# S6E2H1xE register map
Vendor: Cypress; File version: 2.1
CPU: CM4 r0p1, little endian, MPU, FPU, 4 interrupt priority bits
Registers are 32-bit, read-write, reset 0x0 unless marked. A register's access mark holds for its fields unless they carry their own. Offsets are from the block's base; [hi:lo] are bit positions; 'fields as' and 'values as' point back to an identical list.

## MFT0 — Multifunction Timer 0
Base 0x40020000
Same registers: MFT1 0x40021000, MFT2 0x40022000
0x102 OCU_OCCP0 16-bit (OCU view) — OCU ch.0 Compare Value Store Register [HW]
0x106 OCU_OCCP1 16-bit (OCU view) — OCU ch.1 Compare Value Store Register [HW]
0x10A OCU_OCCP2 16-bit (OCU view) — OCU ch.2 Compare Value Store Register [HW]
0x10E OCU_OCCP3 16-bit (OCU view) — OCU ch.3 Compare Value Store Register [HW]
0x112 OCU_OCCP4 16-bit (OCU view) — OCU ch.4 Compare Value Store Register [HW]
0x116 OCU_OCCP5 16-bit (OCU view) — OCU ch.5 Compare Value Store Register [HW]
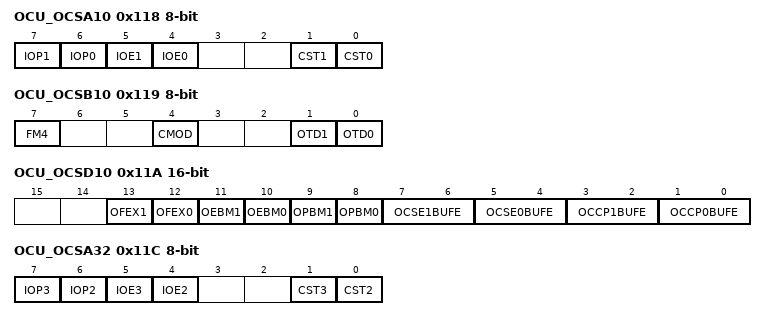
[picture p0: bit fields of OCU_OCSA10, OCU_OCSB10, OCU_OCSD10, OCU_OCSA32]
0x118 OCU_OCSA10 8-bit (OCU view) — OCU ch.0/1 Control Register A [BHW]
  [7] IOP1 — Indicates that a match has already been detected between FRT's count value and OCCP(1) value at OCU ch.(1)
  [6] IOP0 — Indicates that a match has already been detected between FRT's count value and OCCP(0) value at OCU ch.(0)
  [5] IOE1 — Generates interrupt when OCSA.IOP1 is set to 1
  [4] IOE0 — Generates interrupt when OCSA.IOP0 is set to 1
  [1] CST1 — Enables the operation of OCU ch.(1)
  [0] CST0 — Enables the operation of OCU ch.(0)
0x119 OCU_OCSB10 8-bit (OCU view) — OCU ch.0/1 Control Register B [BHW]
  [7] FM4 — selects FM4 mode for operating mode
  [4] CMOD — selects OCU's operation mode in combination with OCSC.MOD0 to MOD5
  [1] OTD1 — Indicates that the RT(1) output pin is in the High-level output state
  [0] OTD0 — Indicates that the RT(0) output pin is in the High-level output state
0x11A OCU_OCSD10 16-bit (OCU view) — OCU ch.0/1 Control Register D [BHW]
  [13] OFEX1 — extends the matching determination conditions of the connected FRT with the OCCP(1) register value
  [12] OFEX0 — extends the matching determination conditions of the connected FRT with the OCCP(0) register value
  [11] OEBM1 — sets the linked transfer settings with the FRT interrupt mask counter
  [10] OEBM0 — sets the linked transfer settings with the FRT interrupt mask counter
  [9] OPBM1 — sets the linked transfer settings with the FRT interrupt mask counter
  [8] OPBM0 — sets the linked transfer settings with the FRT interrupt mask counter
  [7:6] OCSE1BUFE — Enable buffer register function of OCSE(1)
  [5:4] OCSE0BUFE — Enable buffer register function of OCSE(0)
  [3:2] OCCP1BUFE — Enable buffer register function of OCCP(1)
  [1:0] OCCP0BUFE — Enable buffer register function of OCCP(0)
0x11C OCU_OCSA32 8-bit (OCU view) — OCU ch.2/3 Control Register A [BHW]
  [7] IOP3 — Indicates that a match has already been detected between FRT's count value and OCCP(3) value at OCU ch.(3)
  [6] IOP2 — Indicates that a match has already been detected between FRT's count value and OCCP(2) value at OCU ch.(2)
  [5] IOE3 — Generates interrupt when OCSA.IOP3 is set to 1
  [4] IOE2 — Generates interrupt when OCSA.IOP2 is set to 1
  [1] CST3 — Enables the operation of OCU ch.(3)
  [0] CST2 — Enables the operation of OCU ch.(2)
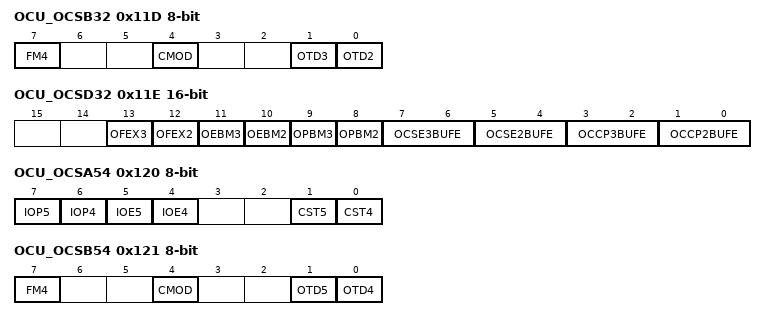
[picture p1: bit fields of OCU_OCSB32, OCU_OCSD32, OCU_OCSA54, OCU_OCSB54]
0x11D OCU_OCSB32 8-bit (OCU view) — OCU ch.2/3 Control Register B [BHW]
  [7] FM4 — selects FM4 mode for operating mode
  [4] CMOD — selects OCU's operation mode in combination with OCSC.MOD0 to MOD5
  [1] OTD3 — Indicates that the RT(3) output pin is in the High-level output state
  [0] OTD2 — Indicates that the RT(2) output pin is in the High-level output state
0x11E OCU_OCSD32 16-bit (OCU view) — OCU ch.2/3 Control Register D [BHW]
  [13] OFEX3 — extends the matching determination conditions of the connected FRT with the OCCP(3) register value
  [12] OFEX2 — extends the matching determination conditions of the connected FRT with the OCCP(2) register value
  [11] OEBM3 — sets the linked transfer settings with the FRT interrupt mask counter
  [10] OEBM2 — sets the linked transfer settings with the FRT interrupt mask counter
  [9] OPBM3 — sets the linked transfer settings with the FRT interrupt mask counter
  [8] OPBM2 — sets the linked transfer settings with the FRT interrupt mask counter
  [7:6] OCSE3BUFE — Enable buffer register function of OCSE(3)
  [5:4] OCSE2BUFE — Enable buffer register function of OCSE(2)
  [3:2] OCCP3BUFE — Enable buffer register function of OCCP(3)
  [1:0] OCCP2BUFE — Enable buffer register function of OCCP(2)
0x120 OCU_OCSA54 8-bit (OCU view) — OCU ch.4/5 Control Register A [BHW]
  [7] IOP5 — Indicates that a match has already been detected between FRT's count value and OCCP(5) value at OCU ch.(5)
  [6] IOP4 — Indicates that a match has already been detected between FRT's count value and OCCP(4) value at OCU ch.(4)
  [5] IOE5 — Generates interrupt when OCSA.IOP5 is set to 1
  [4] IOE4 — Generates interrupt when OCSA.IOP4 is set to 1
  [1] CST5 — Enables the operation of OCU ch.(5)
  [0] CST4 — Enables the operation of OCU ch.(4)
0x121 OCU_OCSB54 8-bit (OCU view) — OCU ch.4/5 Control Register B [BHW]
  [7] FM4 — selects FM4 mode for operating mode
  [4] CMOD — selects OCU's operation mode in combination with OCSC.MOD0 to MOD5
  [1] OTD5 — Indicates that the RT(5) output pin is in the High-level output state
  [0] OTD4 — Indicates that the RT(4) output pin is in the High-level output state
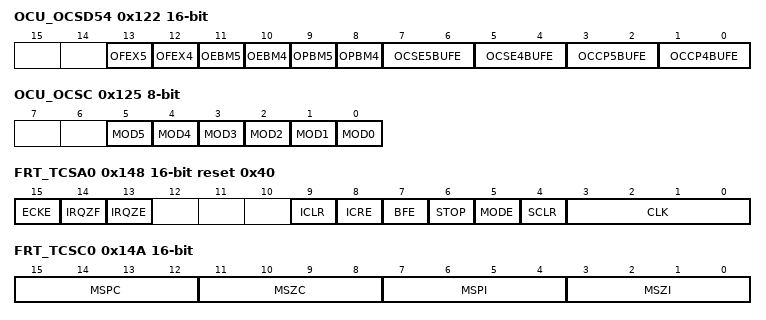
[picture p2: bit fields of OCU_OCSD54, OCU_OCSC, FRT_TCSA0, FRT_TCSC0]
0x122 OCU_OCSD54 16-bit (OCU view) — OCU ch.4/5 Control Register D [BHW]
  [13] OFEX5 — extends the matching determination conditions of the connected FRT with the OCCP(5) register value
  [12] OFEX4 — extends the matching determination conditions of the connected FRT with the OCCP(4) register value
  [11] OEBM5 — sets the linked transfer settings with the FRT interrupt mask counter
  [10] OEBM4 — sets the linked transfer settings with the FRT interrupt mask counter
  [9] OPBM5 — sets the linked transfer settings with the FRT interrupt mask counter
  [8] OPBM4 — sets the linked transfer settings with the FRT interrupt mask counter
  [7:6] OCSE5BUFE — Enable buffer register function of OCSE(5)
  [5:4] OCSE4BUFE — Enable buffer register function of OCSE(4)
  [3:2] OCCP5BUFE — Enable buffer register function of OCCP(5)
  [1:0] OCCP4BUFE — Enable buffer register function of OCCP(4)
0x125 OCU_OCSC 8-bit (OCU view) — OCU Control Register C [BHW]
  [5] MOD5 — OCSC.MOD4 and OCSC.MOD5 determine the operation mode of OCU ch.4,h.5 in combination with OCSB54.CMOD
  [4] MOD4 — OCSC.MOD4 and OCSC.MOD5 determine the operation mode of OCU ch.4,h.5 in combination with OCSB54.CMOD
  [3] MOD3 — OCSC.MOD2 and OCSC.MOD3 determine the operation mode of OCU ch.2,h.3 in combination with OCSB32.CMOD
  [2] MOD2 — OCSC.MOD2 and OCSC.MOD3 determine the operation mode of OCU ch.2,h.3 in combination with OCSB32.CMOD
  [1] MOD1 — OCSC.MOD0 and OCSC.MOD1 determine the operation mode of OCU ch.0,h.1 in combination with OCSB10.CMOD
  [0] MOD0 — OCSC.MOD0 and OCSC.MOD1 determine the operation mode of OCU ch.0,h.1 in combination with OCSB10.CMOD
0x128 OCU_OCSE0 16-bit (OCU view) — OCU ch.0 Control Register E [BHW]
  [15:0] OCSE — specify the setting conditions of the OCU's matching detection register (IOP0)
0x12C OCU_OCSE1 (OCU view) — OCU ch.1 Control Register E [BHW]
  [31:0] OCSE — specify the setting conditions of the OCU's matching detection register (IOP0/IOP1)
0x130 OCU_OCSE2 16-bit (OCU view) — OCU ch.2 Control Register E [BHW]
  fields as OCU_OCSE0
0x134 OCU_OCSE3 (OCU view) — OCU ch.3 Control Register E [BHW]
  fields as OCU_OCSE1
0x138 OCU_OCSE4 16-bit (OCU view) — OCU ch.4 Control Register E [BHW]
  fields as OCU_OCSE0
0x13C OCU_OCSE5 (OCU view) — OCU ch.5 Control Register E [BHW]
  fields as OCU_OCSE1
0x142 FRT_TCCP0 16-bit reset 0xFFFF (FRT view) — FRT-ch.0 Cycle Setting Register [HW]
  [15:0] TCCP — Count Cycle Setting Bits
0x146 FRT_TCDT0 16-bit (FRT view) — FRT-ch.0 Count Value Register [HW]
0x148 FRT_TCSA0 16-bit reset 0x40 (FRT view) — FRT-ch.0 Control Register A [BHW]
  [15] ECKE — Uses an external input clock (FRCK) as FRT's count clock
  [14] IRQZF — zero interrupt flag
  [13] IRQZE — Generates interrupt when TCSA.IRQZF is set to 1
  [9] ICLR — interrupt flag
  [8] ICRE — Generates interrupt when TCSA.ICLR is set to 1
  [7] BFE — Enables TCCP's buffer function
  [6] STOP — Puts FRT in stopping state
  [5] MODE — FRT's count mode
  [4] SCLR wo — FRT operation state initialization request
  [3:0] CLK — FRT clock cycle
0x14A FRT_TCSC0 16-bit (FRT view) — FRT-ch.0 Control Register C [HW]
  [15:12] MSPC ro — Current counter value of a Peak value detection mask counter
  [11:8] MSZC ro — Current counter value of a Zero value detection mask counter
  [7:4] MSPI — Masked Peak value detection number
  [3:0] MSZI — Masked Zero value detection number
0x14E FRT_TCCP1 16-bit reset 0xFFFF (FRT view) — FRT-ch.1 Cycle Setting Register [HW]
  [15:0] TCCP — Count Cycle Setting Bits
0x152 FRT_TCDT1 16-bit (FRT view) — FRT-ch.1 Count Value Register [HW]
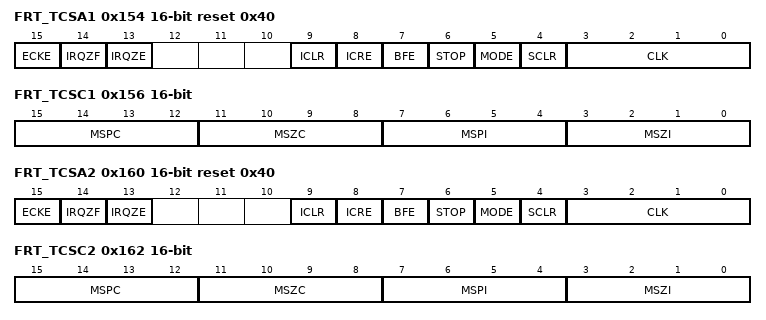
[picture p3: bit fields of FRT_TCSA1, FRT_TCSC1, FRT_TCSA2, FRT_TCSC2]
0x154 FRT_TCSA1 16-bit reset 0x40 (FRT view) — FRT-ch.1 Control Register A [BHW]
  fields as FRT_TCSA0
0x156 FRT_TCSC1 16-bit (FRT view) — FRT-ch.1 Control Register C [HW]
  fields as FRT_TCSC0
0x15A FRT_TCCP2 16-bit reset 0xFFFF (FRT view) — FRT-ch.2 Cycle Setting Register [HW]
  [15:0] TCCP — Count Cycle Setting Bits
0x15E FRT_TCDT2 16-bit (FRT view) — FRT-ch.2 Count Value Register [HW]
0x160 FRT_TCSA2 16-bit reset 0x40 (FRT view) — FRT-ch.2 Control Register A [BHW]
  fields as FRT_TCSA0
0x162 FRT_TCSC2 16-bit (FRT view) — FRT-ch.2 Control Register C [HW]
  fields as FRT_TCSC0
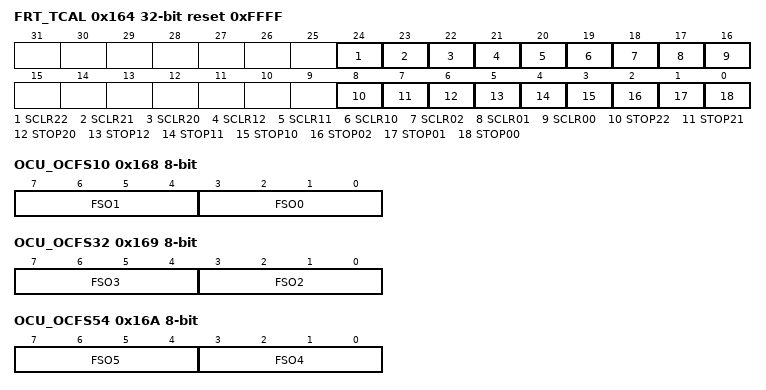
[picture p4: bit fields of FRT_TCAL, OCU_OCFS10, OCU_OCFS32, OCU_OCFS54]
0x164 FRT_TCAL reset 0xFFFF (FRT view) — FRT Simultaneous Start Control Register [W]
  [24] SCLR22 wo — Mirror register of the SCLR bit located in TCSA2 register of MFT-unit2
  [23] SCLR21 wo — Mirror register of the SCLR bit located in TCSA1 register of MFT-unit2
  [22] SCLR20 wo — Mirror register of the SCLR bit located in TCSA0 register of MFT-unit2
  [21] SCLR12 wo — Mirror register of the SCLR bit located in TCSA2 register of MFT-unit1
  [20] SCLR11 wo — Mirror register of the SCLR bit located in TCSA1 register of MFT-unit1
  [19] SCLR10 wo — Mirror register of the SCLR bit located in TCSA0 register of MFT-unit1
  [18] SCLR02 wo — Mirror register of the SCLR bit located in TCSA2 register of MFT-unit0
  [17] SCLR01 wo — Mirror register of the SCLR bit located in TCSA1 register of MFT-unit0
  [16] SCLR00 wo — Mirror register of the SCLR bit located in TCSA0 register of MFT-unit0
  [8] STOP22 — Mirror register of the STOP bit located in TCSA2 register of MFT-unit2
  [7] STOP21 — Mirror register of the STOP bit located in TCSA1 register of MFT-unit2
  [6] STOP20 — Mirror register of the STOP bit located in TCSA0 register of MFT-unit2
  [5] STOP12 — Mirror register of the STOP bit located in TCSA2 register of MFT-unit1
  [4] STOP11 — Mirror register of the STOP bit located in TCSA1 register of MFT-unit1
  [3] STOP10 — Mirror register of the STOP bit located in TCSA0 register of MFT-unit1
  [2] STOP02 — Mirror register of the STOP bit located in TCSA2 register of MFT-unit0
  [1] STOP01 — Mirror register of the STOP bit located in TCSA1 register of MFT-unit0
  [0] STOP00 — Mirror register of the STOP bit located in TCSA0 register of MFT-unit0
0x168 OCU_OCFS10 8-bit (OCU view) — OCU ch.0/1 Connecting FRT Select Register [BHW]
  [7:4] FSO1 — Connects FRT ch.x to OCU ch.1
  [3:0] FSO0 — Connects FRT ch.x to OCU ch.0
0x169 OCU_OCFS32 8-bit (OCU view) — OCU ch.2/3 Connecting FRT Select Register [BHW]
  [7:4] FSO3 — Connects FRT ch.x to OCU ch.3
  [3:0] FSO2 — Connects FRT ch.x to OCU ch.2
0x16A OCU_OCFS54 8-bit (OCU view) — OCU ch.4/5 Connecting FRT Select Register [BHW]
  [7:4] FSO5 — Connects FRT ch.x to OCU ch.5
  [3:0] FSO4 — Connects FRT ch.x to OCU ch.4
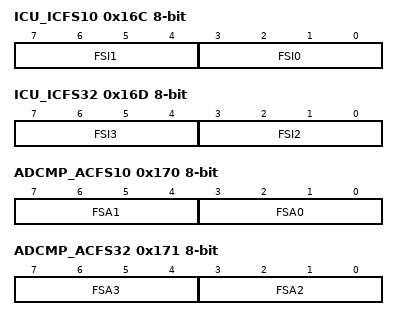
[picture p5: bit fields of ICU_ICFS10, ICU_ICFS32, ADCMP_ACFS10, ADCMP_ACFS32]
0x16C ICU_ICFS10 8-bit (ICU view) — ICU ch.0/1 Connecting FRT Select Register [BHW]
  [7:4] FSI1 — Connects FRT ch.x to ICU ch.(1)
  [3:0] FSI0 — Connects FRT ch.x to ICU ch.(0)
0x16D ICU_ICFS32 8-bit (ICU view) — ICU ch.2/3 Connecting FRT Select Register [BHW]
  [7:4] FSI3 — Connects FRT ch.x to ICU ch.(3)
  [3:0] FSI2 — Connects FRT ch.x to ICU ch.(2)
0x170 ADCMP_ACFS10 8-bit (ADCMP view) — ADCMP ch.0/1 Connecting FRT Select Register [BHW]
  [7:4] FSA1 — specify the FRT to be connected to ADCMP ch.(1)
  [3:0] FSA0 — specify the FRT to be connected to ADCMP ch.(0)
0x171 ADCMP_ACFS32 8-bit (ADCMP view) — ADCMP ch.2/3 Connecting FRT Select Register [BHW]
  [7:4] FSA3 — specify the FRT to be connected to ADCMP ch.(3)
  [3:0] FSA2 — specify the FRT to be connected to ADCMP ch.(2)
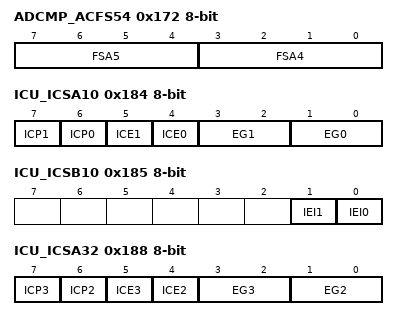
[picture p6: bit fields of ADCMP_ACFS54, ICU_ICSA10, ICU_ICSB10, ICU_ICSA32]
0x172 ADCMP_ACFS54 8-bit (ADCMP view) — ADCMP ch.4/5 Connecting FRT Select Register [BHW]
  [7:4] FSA5 — specify the FRT to be connected to ADCMP ch.(5)
  [3:0] FSA4 — specify the FRT to be connected to ADCMP ch.(4)
0x176 ICU_ICCP0 16-bit ro reset not defined (ICU view) — ICU-ch.0 Capture Value Store Register [HW]
0x17A ICU_ICCP1 16-bit ro reset not defined (ICU view) — ICU-ch.1 Capture Value Store Register [HW]
0x17E ICU_ICCP2 16-bit ro reset not defined (ICU view) — ICU-ch.2 Capture Value Store Register [HW]
0x182 ICU_ICCP3 16-bit ro reset not defined (ICU view) — ICU-ch.3 Capture Value Store Register [HW]
0x184 ICU_ICSA10 8-bit (ICU view) — ICU ch.0/1 Control Register A [BHW]
  [7] ICP1 — Indicates that a valid edge has been detected at ICU ch.(1) and the capture operation has been performed
  [6] ICP0 — Indicates that a valid edge has been detected at ICU ch.(0) and the capture operation has been performed
  [5] ICE1 — Generates interrupt when ICSA.ICP1 is set to 1
  [4] ICE0 — Generates interrupt when ICSA.ICP0 is set to 1
  [3:2] EG1 — enables/disables the operation of ICU-ch.(1) and selects a valid edge(s)
  [1:0] EG0 — enables/disables the operation of ICU-ch.(0) and selects a valid edge(s)
0x185 ICU_ICSB10 8-bit ro (ICU view) — ICU ch.0/1 Control Register B [BHW]
  [1] IEI1 — indicates the latest valid edge of ICU ch.(1)
  [0] IEI0 — indicates the latest valid edge of ICU ch.(0)
0x188 ICU_ICSA32 8-bit (ICU view) — ICU ch.2/3 Control Register A [BHW]
  [7] ICP3 — Indicates that a valid edge has been detected at ICU ch.(3) and the capture operation has been performed
  [6] ICP2 — Indicates that a valid edge has been detected at ICU ch.(2) and the capture operation has been performed
  [5] ICE3 — Generates interrupt when ICSA.ICP3 is set to 1
  [4] ICE2 — Generates interrupt when ICSA.ICP2 is set to 1
  [3:2] EG3 — enables/disables the operation of ICU-ch.(3) and selects a valid edge(s)
  [1:0] EG2 — enables/disables the operation of ICU-ch.(2) and selects a valid edge(s)
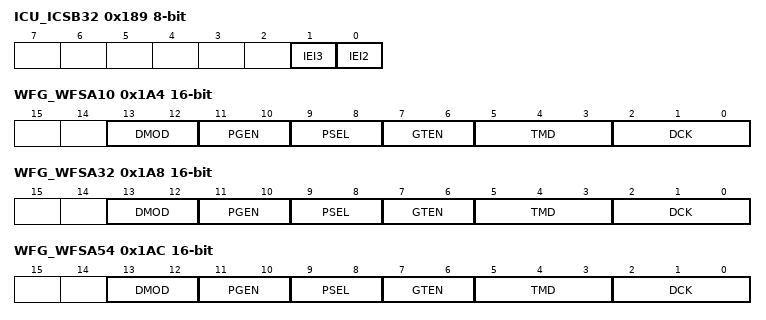
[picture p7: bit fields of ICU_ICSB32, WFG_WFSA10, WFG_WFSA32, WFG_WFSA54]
0x189 ICU_ICSB32 8-bit ro (ICU view) — ICU ch.2/3 Control Register B [BHW]
  [1] IEI3 — indicates the latest valid edge of ICU ch.(3)
  [0] IEI2 — indicates the latest valid edge of ICU ch.(2)
0x18E WFG_WFTF10 16-bit (WFG view) — Pulse Counter Value Register for WFG ch.0/1 [HW]
0x190 WFG_WFTA10 16-bit (WFG view) — WFG Timer Value Register for WFG ch.0/1 [HW]
0x192 WFG_WFTB10 16-bit (WFG view) — WFG Timer Value Register for WFG ch.0/1 [HW]
0x196 WFG_WFTF32 16-bit (WFG view) — Pulse Counter Value Register for WFG ch.2/3 [HW]
0x198 WFG_WFTA32 16-bit (WFG view) — WFG Timer Value Register for WFG ch.2/3 [HW]
0x19A WFG_WFTB32 16-bit (WFG view) — WFG Timer Value Register for WFG ch.2/3 [HW]
0x19E WFG_WFTF54 16-bit (WFG view) — Pulse Counter Value Register for WFG ch.4/5 [HW]
0x1A0 WFG_WFTA54 16-bit (WFG view) — WFG Timer Value Register for WFG ch.4/5 [HW]
0x1A2 WFG_WFTB54 16-bit (WFG view) — WFG Timer Value Register for WFG ch.4/5 [HW]
0x1A4 WFG_WFSA10 16-bit (WFG view) — WFG Control Register A for WFG ch.0/1 [BHW]
  [13:12] DMOD — 1specifies polarity for RTO(0) and RTO(1) signal outputs
  [11:10] PGEN — specifies how to reflect the CH_PPG signal for each channel of the WFG
  [9:8] PSEL — select the PPG timer unit to be used for each channel of the WFG
  [7:6] GTEN — selects the output conditions for the CH_GATE output signal of the WFG
  [5:3] TMD — select the WFG's operation mode
  [2:0] DCK — set the count clock cycle for the WFG timer and Pulse counter
0x1A8 WFG_WFSA32 16-bit (WFG view) — WFG Control Register A for WFG ch.2/3 [BHW]
  fields as WFG_WFSA10
0x1AC WFG_WFSA54 16-bit (WFG view) — WFG Control Register A for WFG ch.4/5 [BHW]
  fields as WFG_WFSA10
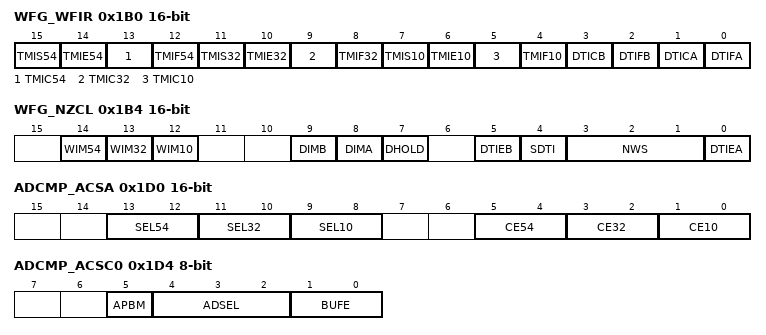
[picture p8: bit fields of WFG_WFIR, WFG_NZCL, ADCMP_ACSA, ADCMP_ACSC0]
0x1B0 WFG_WFIR 16-bit (WFG view) — WFG Interrupt Control Register [HW]
  [15] TMIS54 wo — stops the WFG54 reload timer and clears TMIF54
  [14] TMIE54 — stops the WFG54 reload timer and clears TMIF54
  [13] TMIC54 wo — clears TIMF54 bit
  [12] TMIF54 ro — detects the event of WFG54 reload timer interrupt occurrence
  [11] TMIS32 wo — stops the WFG32 reload timer and clears TMIF32
  [10] TMIE32 — 1stops the WFG32 reload timer and clears TMIF32
  [9] TMIC32 wo — clears TIMF32 bit
  [8] TMIF32 ro — detects the event of WFG32 reload timer interrupt occurrence
  [7] TMIS10 wo — stops the WFG10 reload timer and clears TMIF10
  [6] TMIE10 — starts WFG10 reload timer and checks the operation state of it
  [5] TMIC10 wo — clears TIMF10 bit
  [4] TMIF10 ro — detects the event of WFG10 reload timer interrupt occurrence
  [3] DTICB wo — clears DTIFB bit
  [2] DTIFB ro — detects DTTIX signal input via analog noise filter
  [1] DTICA wo — clears the DTIFA interrupt flag
  [0] DTIFA ro — detects the event of DTTIX signal input via digital noise-canceller
0x1B4 WFG_NZCL 16-bit (WFG view) — NZCL Control Register [HW]
  [14] WIM54 — selects whether a WFG54 reload timer interrupt is masked when the WFIR.TMIF54 flag is set
  [13] WIM32 — selects whether a WFG32 reload timer interrupt is masked when the WFIR.TMIF32 flag is set
  [12] WIM10 — selects whether a WFG10 reload timer interrupt is masked when the WFIR.TMIF10 flag is set
  [9] DIMB — selects whether a DTIF interrupt is masked when the WFIR.TIFDTIFB flag is set
  [8] DIMA — selects whether a DTIF interrupt is masked when the WFIR.DTIFA flag is set
  [7] DHOLD — selects whether the RTO output signal of WFG is held when the DTIF interrupt signal is asserted
  [5] DTIEB — Enables the path from DTTIX pin to analog noise filter
  [4] SDTI wo — sets the WFIR.DTIFA register by writing to the register from the CPU
  [3:1] NWS — set the noise-canceling width for a digital noise-canceller
  [0] DTIEA — Enables the path for digital noise filter from DTTIX pin
0x1BA ADCMP_ACMP0 16-bit (ADCMP view) — ADCMP ch.0 Compare Value Store Register [HW]
  [15:0] ACMP — 0
0x1BE ADCMP_ACMP1 16-bit (ADCMP view) — ADCMP ch.1 Compare Value Store Register [HW]
  [15:0] ACMP — 0
0x1C2 ADCMP_ACMP2 16-bit (ADCMP view) — ADCMP ch.2 Compare Value Store Register [HW]
  [15:0] ACMP — 0
0x1C6 ADCMP_ACMP3 16-bit (ADCMP view) — ADCMP ch.3 Compare Value Store Register [HW]
  [15:0] ACMP — 0
0x1CA ADCMP_ACMP4 16-bit (ADCMP view) — ADCMP ch.4 Compare Value Store Register [HW]
  [15:0] ACMP — 0
0x1CE ADCMP_ACMP5 16-bit (ADCMP view) — ADCMP ch.5 Compare Value Store Register [HW]
  [15:0] ACMP — 0
0x1D0 ADCMP_ACSA 16-bit (ADCMP view) — ADCMP Control Register A [BHW]
  [13:12] SEL54 — selects compatible operation of ADCMP ch.5 and ch.4 with FM3 Family products
  [11:10] SEL32 — selects compatible operation of ADCMP ch.3 and ch.2 with FM3 Family products
  [9:8] SEL10 — selects compatible operation of ADCMP ch.1 and ch.0 with FM3 Family products
  [5:4] CE54 — enables/disables compatibility of ADCMP ch.5 and ch.4 with FM3 Family products
  [3:2] CE32 — enables/disables compatibility of ADCMP ch.3 and ch.2 with FM3 Family products
  [1:0] CE10 — enables/disables compatibility of ADCMP ch.1 and ch.0 with FM3 Family products
0x1D4 ADCMP_ACSC0 8-bit (ADCMP view) — ADCMP ch.0 Control Register C [BHW]
  [5] APBM — sets the linked transfer with the FRT interrupt mask counter
  [4:2] ADSEL — specify the destinations of ADC start signals that are output by ADCMP
  [1:0] BUFE — select enable/disable and transfer timing for buffer function of the ACMP register
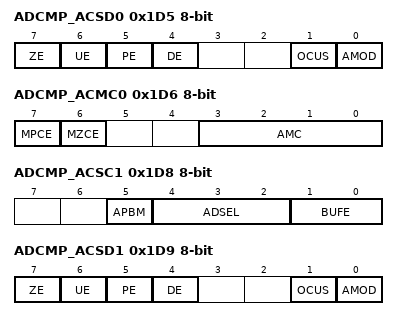
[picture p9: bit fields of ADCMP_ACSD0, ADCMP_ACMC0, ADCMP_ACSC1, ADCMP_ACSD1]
0x1D5 ADCMP_ACSD0 8-bit (ADCMP view) — ADCMP ch.0 Control Register D [BHW]
  [7] ZE — enables/disables the operation of the ADCMP when the FRT is 0x0000
  [6] UE — enables/disables the operation of the ADCMP that is counting up for the connected FRT
  [5] PE — enables/disables the operation of the ADCMP that is counting down at the Peak value of the connected FRT
  [4] DE — enables/disables the operation of the ADCMP that is counting down for the connected FRT
  [1] OCUS — selects the OCU OCCP register that will become the start for offset start
  [0] AMOD — selects operation mode for ADCMP
0x1D6 ADCMP_ACMC0 8-bit (ADCMP view) — ADCMP ch.0 Mask Compare Value Storage Register [BHW]
  [7] MPCE — specifies whether a comparison is performed with the FRT peak interrupt mask counter
  [6] MZCE — specifies whether a comparison is performed with the FRT zero interrupt mask counter
  [3:0] AMC — specifies the value to be compared with the FRT interrupt mask counter
0x1D8 ADCMP_ACSC1 8-bit (ADCMP view) — ADCMP ch.1 Control Register C [BHW]
  fields as ADCMP_ACSC0
0x1D9 ADCMP_ACSD1 8-bit (ADCMP view) — ADCMP ch.1 Control Register D [BHW]
  fields as ADCMP_ACSD0
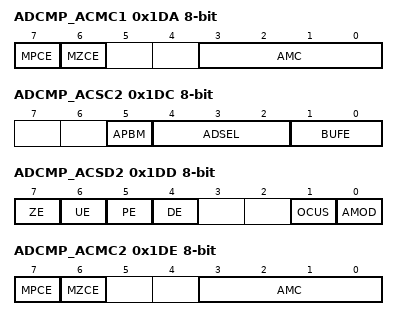
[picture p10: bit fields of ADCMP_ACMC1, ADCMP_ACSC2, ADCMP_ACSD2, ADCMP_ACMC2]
0x1DA ADCMP_ACMC1 8-bit (ADCMP view) — ADCMP ch.1 Mask Compare Value Storage Register [BHW]
  fields as ADCMP_ACMC0
0x1DC ADCMP_ACSC2 8-bit (ADCMP view) — ADCMP ch.2 Control Register C [BHW]
  fields as ADCMP_ACSC0
0x1DD ADCMP_ACSD2 8-bit (ADCMP view) — ADCMP ch.2 Control Register D [BHW]
  fields as ADCMP_ACSD0
0x1DE ADCMP_ACMC2 8-bit (ADCMP view) — ADCMP ch.2 Mask Compare Value Storage Register [BHW]
  fields as ADCMP_ACMC0
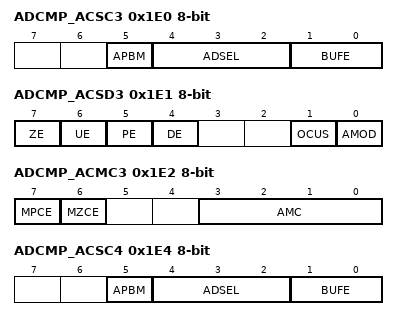
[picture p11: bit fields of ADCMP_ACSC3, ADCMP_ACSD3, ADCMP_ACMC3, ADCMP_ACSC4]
0x1E0 ADCMP_ACSC3 8-bit (ADCMP view) — ADCMP ch.3 Control Register C [BHW]
  fields as ADCMP_ACSC0
0x1E1 ADCMP_ACSD3 8-bit (ADCMP view) — ADCMP ch.3 Control Register D [BHW]
  fields as ADCMP_ACSD0
0x1E2 ADCMP_ACMC3 8-bit (ADCMP view) — ADCMP ch.3 Mask Compare Value Storage Register [BHW]
  fields as ADCMP_ACMC0
0x1E4 ADCMP_ACSC4 8-bit (ADCMP view) — ADCMP ch.4 Control Register C [BHW]
  fields as ADCMP_ACSC0
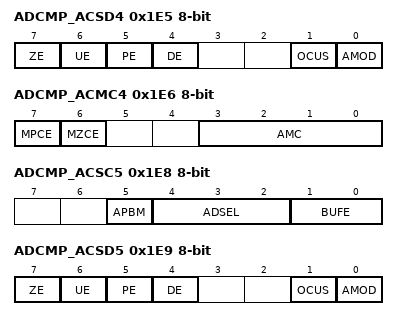
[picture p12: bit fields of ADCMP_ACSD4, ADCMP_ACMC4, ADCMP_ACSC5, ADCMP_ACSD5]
0x1E5 ADCMP_ACSD4 8-bit (ADCMP view) — ADCMP ch.4 Control Register D [BHW]
  fields as ADCMP_ACSD0
0x1E6 ADCMP_ACMC4 8-bit (ADCMP view) — ADCMP ch.4 Mask Compare Value Storage Register [BHW]
  fields as ADCMP_ACMC0
0x1E8 ADCMP_ACSC5 8-bit (ADCMP view) — ADCMP ch.5 Control Register C [BHW]
  fields as ADCMP_ACSC0
0x1E9 ADCMP_ACSD5 8-bit (ADCMP view) — ADCMP ch.5 Control Register D [BHW]
  fields as ADCMP_ACSD0
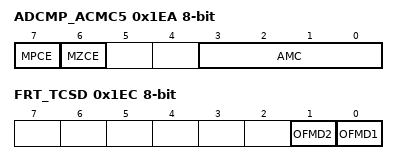
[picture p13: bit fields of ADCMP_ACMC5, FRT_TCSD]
0x1EA ADCMP_ACMC5 8-bit (ADCMP view) — ADCMP ch.5 Mask Compare Value Storage Register [BHW]
  fields as ADCMP_ACMC0
0x1EC FRT_TCSD 8-bit (FRT view) — FRT Control Register D [BHW]
  [1] OFMD2 — selects the count mode with offset for FRT ch.2
  [0] OFMD1 — selects the count mode with offset for FRT ch.1

## Notices in the file
Copyright (C) 2013-2016, Cypress Semiconductor Corporation or a
subsidiary of Cypress Semiconductor Corporation.  All rights reserved.
This software, including source code, documentation and related
materials ("Software"), is owned by Cypress Semiconductor Corporation or
one of its subsidiaries ("Cypress") and is protected by and subject to
worldwide patent protection (United States and foreign), United States
copyright laws and international treaty provisions. Therefore, you may use
this Software only as provided in the license agreement accompanying the
software package from which you obtained this Software ("EULA").
If no EULA applies, Cypress hereby grants you a personal, non-exclusive,
non-transferable license to copy, modify, and compile the
Software source code solely for use in connection with Cypress's
integrated circuit products.  Any reproduction, modification, translation,
compilation, or representation of this Software except as specified
above is prohibited without the express written permission of Cypress.
Disclaimer: THIS SOFTWARE IS PROVIDED AS-IS, WITH NO
WARRANTY OF ANY KIND, EXPRESS OR IMPLIED, INCLUDING,
BUT NOT LIMITED TO, NONINFRINGEMENT, IMPLIED
WARRANTIES OF MERCHANTABILITY AND FITNESS FOR A
PARTICULAR PURPOSE. Cypress reserves the right to make
changes to the Software without notice. Cypress does not assume any
liability arising out of the application or use of the Software or any
product or circuit described in the Software. Cypress does not
authorize its products for use in any products where a malfunction or
failure of the Cypress product may reasonably be expected to result in
significant property damage, injury or death ("High Risk Product"). By
including Cypress's product in a High Risk Product, the manufacturer
of such system or application assumes all risk of such use and in doing
so agrees to indemnify Cypress against all liability.
